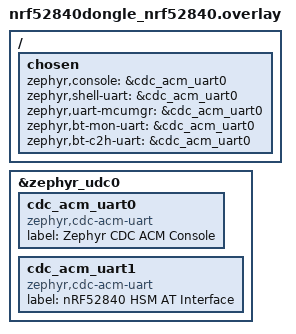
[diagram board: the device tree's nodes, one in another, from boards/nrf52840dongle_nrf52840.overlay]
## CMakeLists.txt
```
cmake_minimum_required(VERSION 3.20.0)

find_package(Zephyr REQUIRED HINTS $ENV{ZEPHYR_BASE})
project(hsm_app)

# Add pure HSM logic library
add_subdirectory(${CMAKE_CURRENT_SOURCE_DIR}/../lib ${CMAKE_CURRENT_BINARY_DIR}/lib)

target_sources(app PRIVATE
    src/main.c
    src/led_status.c
    src/usb_serial.c
    src/dfu_service.c
)

target_link_libraries(app PRIVATE hsm_core)
```

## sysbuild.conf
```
# Dual-Stage Secure Boot Configuration (B0 Immutable -> MCUboot -> Signed App)
SB_CONFIG_BOOTLOADER_MCUBOOT=y
SB_CONFIG_SECURE_BOOT_APPCORE=y
SB_CONFIG_PARTITION_MANAGER=y

# Signature verification using root-level ECDSA P-256 key
SB_CONFIG_BOOT_SIGNATURE_KEY_FILE="../keys/root-ec-p256.pem"
```

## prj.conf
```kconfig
# General Kernel & C library
CONFIG_MAIN_STACK_SIZE=8192
CONFIG_SYSTEM_WORKQUEUE_STACK_SIZE=2048
CONFIG_HEAP_MEM_POOL_SIZE=8192
CONFIG_NEWLIB_LIBC=y
CONFIG_REBOOT=y

# Logging
CONFIG_LOG=y
CONFIG_LOG_MODE_IMMEDIATE=y
CONFIG_LOG_DEFAULT_LEVEL=3
CONFIG_USE_SEGGER_RTT=y
CONFIG_SEGGER_RTT_BUFFER_SIZE_UP=4096
CONFIG_LOG_BACKEND_RTT=y
CONFIG_LOG_BACKEND_UART=y

# Hardware Drivers
CONFIG_GPIO=y
CONFIG_PWM=y
CONFIG_LED=y
CONFIG_LED_PWM=y
CONFIG_HWINFO=y

# Flash & Storage
CONFIG_FLASH=y
CONFIG_FLASH_PAGE_LAYOUT=y
CONFIG_FLASH_MAP=y
CONFIG_STREAM_FLASH=y
CONFIG_NVS=y
CONFIG_SETTINGS=y

# PSA Crypto & CC310 Hardware Acceleration
CONFIG_PSA_CRYPTO=y
CONFIG_PSA_CRYPTO_DRIVER_OBERON=n
CONFIG_PSA_CRYPTO_DRIVER_CC3XX=y
CONFIG_PSA_WANT_ALG_ECDSA=y
CONFIG_PSA_WANT_ALG_ECDH=y
CONFIG_PSA_WANT_ALG_GCM=y
CONFIG_PSA_WANT_KEY_TYPE_AES=y
CONFIG_PSA_WANT_KEY_TYPE_ECC_KEY_PAIR_GENERATE=y
CONFIG_PSA_WANT_KEY_TYPE_ECC_KEY_PAIR_IMPORT=y
CONFIG_PSA_WANT_KEY_TYPE_ECC_KEY_PAIR_EXPORT=y
CONFIG_PSA_WANT_ECC_SECP_R1_256=y
CONFIG_PSA_WANT_ALG_SHA_256=y
CONFIG_PSA_WANT_GENERATE_RANDOM=y
CONFIG_MBEDTLS_PSA_CRYPTO_STORAGE_C=y
CONFIG_SECURE_STORAGE=y
CONFIG_SECURE_STORAGE_ITS_TRANSFORM_AEAD_SCHEME_CHACHA20_POLY1305=y
CONFIG_MBEDTLS_ENABLE_HEAP=y
CONFIG_MBEDTLS_HEAP_SIZE=8192

# USB Device Stack
CONFIG_USB_DEVICE_STACK=y
CONFIG_USB_DEVICE_PRODUCT="nRF52840 HSM Dongle"
CONFIG_USB_DEVICE_MANUFACTURER="pid.codes"
CONFIG_USB_DEVICE_SN="000000000000"
CONFIG_USB_DEVICE_VID=0x1209
CONFIG_USB_DEVICE_PID=0x0001
CONFIG_USB_CDC_ACM=y
CONFIG_USB_COMPOSITE_DEVICE=y
CONFIG_USB_MAX_NUM_TRANSFERS=16
CONFIG_USB_DEVICE_STACK_NEXT=n
CONFIG_UDC_NRF=n
CONFIG_UDC_DRIVER=n
CONFIG_USBD_CDC_ACM_CLASS=n

# Serial & Console over CDC ACM
CONFIG_SERIAL=y
CONFIG_CONSOLE=y
CONFIG_UART_CONSOLE=y
CONFIG_UART_LINE_CTRL=y
CONFIG_RING_BUFFER=y

# Bootloader / DFU MCUboot support
CONFIG_BOOTLOADER_MCUBOOT=y
CONFIG_IMG_MANAGER=y
CONFIG_MCUBOOT_IMG_MANAGER=y
```

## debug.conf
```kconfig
# Debug configuration overlay
CONFIG_LOG_DEFAULT_LEVEL=4
CONFIG_ASSERT=y
CONFIG_ASSERT_LEVEL=2
CONFIG_DEBUG_OPTIMIZATIONS=y
```

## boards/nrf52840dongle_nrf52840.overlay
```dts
/*
 * Devicetree overlay for nRF52840 Dongle (PCA10059)
 * Exposes two CDC ACM Virtual COM Ports:
 *  - cdc_acm_uart0: Zephyr Console & Logging
 *  - cdc_acm_uart1: Dedicated HSM AT Command / Response Channel
 */

/ {
	chosen {
		zephyr,console = &cdc_acm_uart0;
		zephyr,shell-uart = &cdc_acm_uart0;
		zephyr,uart-mcumgr = &cdc_acm_uart0;
		zephyr,bt-mon-uart = &cdc_acm_uart0;
		zephyr,bt-c2h-uart = &cdc_acm_uart0;
	};
};

&zephyr_udc0 {
	/delete-node/ board_cdc_acm_uart;

	cdc_acm_uart0: cdc_acm_uart0 {
		compatible = "zephyr,cdc-acm-uart";
		label = "Zephyr CDC ACM Console";
	};

	cdc_acm_uart1: cdc_acm_uart1 {
		compatible = "zephyr,cdc-acm-uart";
		label = "nRF52840 HSM AT Interface";
	};
};
```

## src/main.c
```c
#include <zephyr/kernel.h>
#include <zephyr/logging/log.h>
#include <hsm/hsm_core.h>
#include <hsm/crypto_cc310.h>
#include <hsm/keystore.h>
#include <hsm/at_commands.h>
#include "led_status.h"
#include "usb_serial.h"
#include "dfu_service.h"

LOG_MODULE_REGISTER(main, CONFIG_LOG_DEFAULT_LEVEL);

static void on_keystore_state_changed(bool authenticated, uint8_t retries, uint8_t key_count) {
    LOG_INF("Keystore state changed: auth=%d, retries=%u, keys=%u",
            authenticated ? 1 : 0, retries, key_count);

    if (retries == 0) {
        /* Blocked / Lockout -> Solid RED */
        led_status_set_state(HSM_STATE_LOCKED);
    } else if (authenticated) {
        /* Authenticated / Unlocked -> Solid GREEN */
        led_status_set_state(HSM_STATE_UNLOCKED);
    } else if (!keystore_is_configured()) {
        /* Unconfigured / Empty -> Breathing WHITE */
        led_status_set_state(HSM_STATE_UNCONFIGURED);
    } else {
        /* Configured but locked -> Solid RED */
        led_status_set_state(HSM_STATE_LOCKED);
    }
}

int main(void) {
    LOG_INF("==================================================");
    LOG_INF(" nRF52840 HSM Dongle Firmware (PCA10059)");
    LOG_INF(" AT Protocol Engine | Dual-Stage Secure Boot");
    LOG_INF(" Arm CryptoCell CC310 Hardware Acceleration");
    LOG_INF("==================================================");

    /* 1. Initialize Visual LED Indicator */
    led_status_init();

    /* 2. Initialize CryptoCell CC310 / PSA Crypto */
    crypto_cc310_init();

    /* 3. Initialize Persistent Keystore & Auth Supervisor */
    keystore_init(on_keystore_state_changed);

    /* 4. Initialize AT Command Processor */
    at_commands_init();

    /* 5. Initialize DFU Flash Service & Register AT Callbacks */
    dfu_service_init();
    static const at_dfu_callbacks_t dfu_cbs = {
        .write_chunk = dfu_service_write_chunk,
        .apply = dfu_service_apply,
        .get_info = dfu_service_get_info,
    };
    at_commands_register_dfu_callbacks(&dfu_cbs);

    /* 6. Initialize Dual USB CDC ACM (Console + AT Protocol) */
    usb_serial_init();
    LOG_INF("Dongle USB Serial (BLE Address): %s", usb_serial_get_ble_address());

    LOG_INF("HSM AT Protocol Engine ready. Entering polling loop...");

    /* Main polling loop */
    while (1) {
        usb_serial_poll();
        k_msleep(2);
    }

    return 0;
}
```

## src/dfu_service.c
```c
#include <zephyr/kernel.h>
#include <zephyr/storage/flash_map.h>
#include <zephyr/dfu/mcuboot.h>
#include <zephyr/sys/reboot.h>
#include <zephyr/logging/log.h>
#include <psa/crypto.h>
#include <string.h>
#include "dfu_service.h"

LOG_MODULE_REGISTER(dfu_service, CONFIG_LOG_DEFAULT_LEVEL);

static struct k_work_delayable s_reboot_work;

static void reboot_work_handler(struct k_work *work) {
    ARG_UNUSED(work);
    LOG_INF("Executing deferred cold reboot into MCUboot...");
    sys_reboot(SYS_REBOOT_COLD);
}

int dfu_service_init(void) {
    k_work_init_delayable(&s_reboot_work, reboot_work_handler);

    if (!boot_is_img_confirmed()) {
        int rc = boot_write_img_confirmed();
        if (rc != 0) {
            LOG_ERR("Failed to confirm running MCUboot image: %d", rc);
        } else {
            LOG_INF("Running MCUboot image confirmed as permanent.");
        }
    }

    LOG_INF("DFU Service initialized for MCUboot secondary slot.");
    return 0;
}

int dfu_service_get_info(uint8_t *major, uint8_t *minor, uint8_t *patch,
                         uint32_t *active_slot, uint32_t *image_size, uint8_t sha256[32]) {
    if (!major || !minor || !patch || !active_slot || !image_size || !sha256) {
        return -1;
    }

    *major = 1;
    *minor = 0;
    *patch = 0;
    *active_slot = 0;
    *image_size = 0;
    memset(sha256, 0, 32);

    const struct flash_area *fa = NULL;
    int rc = flash_area_open(FLASH_AREA_ID(image_0), &fa);
    if (rc != 0 || !fa) {
        LOG_ERR("Failed to open flash area image_0: %d", rc);
        return rc != 0 ? rc : -1;
    }

    uint32_t size_to_hash = (uint32_t)fa->fa_size;
    struct mcuboot_img_header hdr = {0};
    if (boot_read_bank_header(FLASH_AREA_ID(image_0), &hdr, sizeof(hdr)) == 0 &&
        hdr.mcuboot_version == 1 &&
        hdr.h.v1.image_size > 0 &&
        hdr.h.v1.image_size <= fa->fa_size) {
        size_to_hash = hdr.h.v1.image_size;
    }
    *image_size = size_to_hash;

    psa_hash_operation_t op = PSA_HASH_OPERATION_INIT;
    psa_status_t status = psa_hash_setup(&op, PSA_ALG_SHA_256);
    if (status == PSA_SUCCESS) {
        uint8_t buf[256];
        uint32_t offset = 0;
        while (offset < size_to_hash) {
            uint32_t chunk = size_to_hash - offset;
            if (chunk > sizeof(buf)) {
                chunk = sizeof(buf);
            }
            if (flash_area_read(fa, offset, buf, chunk) != 0) {
                psa_hash_abort(&op);
                break;
            }
            if (psa_hash_update(&op, buf, chunk) != PSA_SUCCESS) {
                psa_hash_abort(&op);
                break;
            }
            offset += chunk;
        }
        if (offset == size_to_hash) {
            size_t hash_len = 0;
            (void)psa_hash_finish(&op, sha256, 32, &hash_len);
        }
    }

    flash_area_close(fa);
    return 0;
}

int dfu_service_write_chunk(uint32_t offset, const uint8_t *data, size_t len) {
    const struct flash_area *fa = NULL;
    int rc = flash_area_open(FLASH_AREA_ID(image_1), &fa);
    if (rc != 0) {
        LOG_ERR("Failed to open flash area image_1: %d", rc);
        return rc;
    }

    if (offset == 0) {
        LOG_INF("Erasing secondary slot before write...");
        rc = flash_area_erase(fa, 0, fa->fa_size);
        if (rc != 0) {
            LOG_ERR("Failed to erase slot 1: %d", rc);
            flash_area_close(fa);
            return rc;
        }
    }

    /* Align write length to 4-byte flash write word boundary (padding with 0xFF) */
    const uint8_t *write_buf = data;
    uint8_t padded_buf[256 + 4];
    size_t write_len = len;

    size_t rem = len % 4;
    if (rem != 0) {
        size_t pad = 4 - rem;
        write_len = len + pad;
        if (write_len <= sizeof(padded_buf)) {
            memcpy(padded_buf, data, len);
            memset(padded_buf + len, 0xff, pad);
            write_buf = padded_buf;
        }
    }

    rc = flash_area_write(fa, offset, write_buf, write_len);
    flash_area_close(fa);

    if (rc != 0) {
        LOG_ERR("Failed to write chunk at offset 0x%x (len %zu): %d", offset, len, rc);
        return rc;
    }

    return 0;
}

int dfu_service_apply(void) {
    LOG_INF("Marking MCUboot upgrade image for test...");
    int rc = boot_request_upgrade(BOOT_UPGRADE_TEST);
    if (rc != 0) {
        LOG_ERR("boot_request_upgrade failed: %d", rc);
        return rc;
    }

    LOG_INF("Scheduling cold reboot into MCUboot in 200 ms...");
    k_work_schedule(&s_reboot_work, K_MSEC(200));
    return 0;
}
```

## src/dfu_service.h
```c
#ifndef DFU_SERVICE_H_
#define DFU_SERVICE_H_

#include <stdint.h>
#include <stddef.h>

#ifdef __cplusplus
extern "C" {
#endif

int dfu_service_init(void);
int dfu_service_write_chunk(uint32_t offset, const uint8_t *data, size_t len);
int dfu_service_apply(void);
int dfu_service_get_info(uint8_t *major, uint8_t *minor, uint8_t *patch,
                         uint32_t *active_slot, uint32_t *image_size, uint8_t sha256[32]);

#ifdef __cplusplus
}
#endif

#endif /* DFU_SERVICE_H_ */
```

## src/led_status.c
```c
#include <zephyr/kernel.h>
#include <zephyr/drivers/gpio.h>
#include <zephyr/drivers/pwm.h>
#include <zephyr/logging/log.h>
#include "led_status.h"

LOG_MODULE_REGISTER(led_status, CONFIG_LOG_DEFAULT_LEVEL);

/* RGB LED GPIO nodes on PCA10059 */
static const struct gpio_dt_spec s_led_red   = GPIO_DT_SPEC_GET(DT_NODELABEL(led1_red), gpios);
static const struct gpio_dt_spec s_led_green = GPIO_DT_SPEC_GET(DT_NODELABEL(led1_green), gpios);
static const struct gpio_dt_spec s_led_blue  = GPIO_DT_SPEC_GET(DT_NODELABEL(led1_blue), gpios);

/* RGB LED PWM nodes on PCA10059 */
#if DT_NODE_EXISTS(DT_NODELABEL(red_pwm_led))
static const struct pwm_dt_spec s_pwm_red = PWM_DT_SPEC_GET(DT_NODELABEL(red_pwm_led));
#endif

#if DT_NODE_EXISTS(DT_NODELABEL(green_pwm_led))
static const struct pwm_dt_spec s_pwm_green = PWM_DT_SPEC_GET(DT_NODELABEL(green_pwm_led));
#endif

#if DT_NODE_EXISTS(DT_NODELABEL(blue_pwm_led))
static const struct pwm_dt_spec s_pwm_blue = PWM_DT_SPEC_GET(DT_NODELABEL(blue_pwm_led));
#endif

static volatile hsm_state_t s_current_state = HSM_STATE_UNCONFIGURED;
static struct k_thread s_led_thread;
static K_THREAD_STACK_DEFINE(s_led_stack, 1024);
static struct k_sem s_state_sem;

static void led_thread_fn(void *arg1, void *arg2, void *arg3) {
    ARG_UNUSED(arg1);
    ARG_UNUSED(arg2);
    ARG_UNUSED(arg3);

    bool pwm_red_ready = false;
    bool pwm_green_ready = false;
    bool pwm_blue_ready = false;

#if DT_NODE_EXISTS(DT_NODELABEL(red_pwm_led))
    pwm_red_ready = device_is_ready(s_pwm_red.dev);
#endif
#if DT_NODE_EXISTS(DT_NODELABEL(green_pwm_led))
    pwm_green_ready = device_is_ready(s_pwm_green.dev);
#endif
#if DT_NODE_EXISTS(DT_NODELABEL(blue_pwm_led))
    pwm_blue_ready = device_is_ready(s_pwm_blue.dev);
#endif

    int breath_counter = 0;
    int breath_dir = 1;

    while (1) {
        hsm_state_t st = s_current_state;

        switch (st) {
        case HSM_STATE_UNCONFIGURED: {
            /*
             * Synchronous white breathing glow across Red, Green, and Blue channels.
             * 3.0s total period: 50 steps up + 50 steps down at 30ms/step = 3000ms.
             */
            uint32_t duty = (uint32_t)(breath_counter * 2); /* 0% to 100% */

            if (pwm_red_ready) {
                uint32_t pulse_r = (uint32_t)((uint64_t)s_pwm_red.period * duty / 100);
                pwm_set_pulse_dt(&s_pwm_red, pulse_r);
            }
            if (pwm_green_ready) {
                uint32_t pulse_g = (uint32_t)((uint64_t)s_pwm_green.period * duty / 100);
                pwm_set_pulse_dt(&s_pwm_green, pulse_g);
            }
            if (pwm_blue_ready) {
                uint32_t pulse_b = (uint32_t)((uint64_t)s_pwm_blue.period * duty / 100);
                pwm_set_pulse_dt(&s_pwm_blue, pulse_b);
            }

            if (!pwm_red_ready || !pwm_green_ready || !pwm_blue_ready) {
                int on = (duty > 50) ? 1 : 0;
                gpio_pin_set_dt(&s_led_red, on);
                gpio_pin_set_dt(&s_led_green, on);
                gpio_pin_set_dt(&s_led_blue, on);
            }

            breath_counter += breath_dir;
            if (breath_counter >= 50) {
                breath_counter = 50;
                breath_dir = -1;
            } else if (breath_counter <= 0) {
                breath_counter = 0;
                breath_dir = 1;
            }

            /* Wait 30ms or wake immediately upon state transition */
            (void)k_sem_take(&s_state_sem, K_MSEC(30));
            break;
        }

        case HSM_STATE_LOCKED: {
            /*
             * Configured & Locked State:
             * Blue and Green strictly 0% (OFF), Red 100% solid ON.
             */
            if (pwm_blue_ready) {
                pwm_set_pulse_dt(&s_pwm_blue, 0);
            }
            if (pwm_green_ready) {
                pwm_set_pulse_dt(&s_pwm_green, 0);
            }
            if (pwm_red_ready) {
                pwm_set_pulse_dt(&s_pwm_red, s_pwm_red.period);
            }

            gpio_pin_set_dt(&s_led_blue, 0);
            gpio_pin_set_dt(&s_led_green, 0);
            gpio_pin_set_dt(&s_led_red, 1);

            /* Sleep until next state transition signal */
            (void)k_sem_take(&s_state_sem, K_FOREVER);
            break;
        }

        case HSM_STATE_UNLOCKED: {
            /*
             * Authenticated State:
             * Red and Blue strictly OFF (0%), Green 100% solid ON.
             */
            if (pwm_red_ready) {
                pwm_set_pulse_dt(&s_pwm_red, 0);
            }
            if (pwm_blue_ready) {
                pwm_set_pulse_dt(&s_pwm_blue, 0);
            }
            if (pwm_green_ready) {
                pwm_set_pulse_dt(&s_pwm_green, s_pwm_green.period);
            }

            gpio_pin_set_dt(&s_led_red, 0);
            gpio_pin_set_dt(&s_led_blue, 0);
            gpio_pin_set_dt(&s_led_green, 1);

            /* Sleep until next state transition signal */
            (void)k_sem_take(&s_state_sem, K_FOREVER);
            break;
        }
        }
    }
}

int led_status_init(void) {
    k_sem_init(&s_state_sem, 0, 1);

    if (!gpio_is_ready_dt(&s_led_red) || !gpio_is_ready_dt(&s_led_green) || !gpio_is_ready_dt(&s_led_blue)) {
        LOG_WRN("GPIO LED devices not all ready");
    }

    gpio_pin_configure_dt(&s_led_red, GPIO_OUTPUT_INACTIVE);
    gpio_pin_configure_dt(&s_led_green, GPIO_OUTPUT_INACTIVE);
    gpio_pin_configure_dt(&s_led_blue, GPIO_OUTPUT_INACTIVE);

    k_thread_create(&s_led_thread, s_led_stack,
                    K_THREAD_STACK_SIZEOF(s_led_stack),
                    led_thread_fn,
                    NULL, NULL, NULL,
                    K_PRIO_COOP(7), 0, K_NO_WAIT);
    k_thread_name_set(&s_led_thread, "led_status");

    return 0;
}

void led_status_set_state(hsm_state_t state) {
    s_current_state = state;
    /* Wake thread immediately (< 50ms) */
    k_sem_give(&s_state_sem);
}
```

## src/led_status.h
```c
#ifndef LED_STATUS_H_
#define LED_STATUS_H_

#include <hsm/hsm_core.h>

#ifdef __cplusplus
extern "C" {
#endif

int led_status_init(void);
void led_status_set_state(hsm_state_t state);

#ifdef __cplusplus
}
#endif

#endif /* LED_STATUS_H_ */
```

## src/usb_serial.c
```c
#include <zephyr/kernel.h>
#include <zephyr/device.h>
#include <zephyr/drivers/uart.h>
#include <zephyr/drivers/hwinfo.h>
#include <zephyr/usb/usb_device.h>
#include <zephyr/usb/usb_ch9.h>
#include <zephyr/logging/log.h>
#include <hal/nrf_ficr.h>
#include <stdio.h>
#include <string.h>
#include <hsm/at_parser.h>
#include <hsm/at_commands.h>
#include "usb_serial.h"

LOG_MODULE_REGISTER(usb_serial, CONFIG_LOG_DEFAULT_LEVEL);

#ifndef USB_BSTRING_LENGTH
#define USB_BSTRING_LENGTH(s) (sizeof(s) * 2 - 2)
#endif
#ifndef USB_STRING_DESCRIPTOR_LENGTH
#define USB_STRING_DESCRIPTOR_LENGTH(s) (sizeof(s) * 2)
#endif

#define CONSOLE_IF_STR "Zephyr CDC ACM Console"
#define HSM_IF_STR     "nRF52840 HSM AT Interface"

struct usb_console_if_string_desc {
	uint8_t bLength;
	uint8_t bDescriptorType;
	uint8_t bString[USB_BSTRING_LENGTH(CONSOLE_IF_STR)];
} __packed;

struct usb_hsm_if_string_desc {
	uint8_t bLength;
	uint8_t bDescriptorType;
	uint8_t bString[USB_BSTRING_LENGTH(HSM_IF_STR)];
} __packed;

USBD_STRING_DESCR_USER_DEFINE(primary) struct usb_console_if_string_desc s_console_str_desc = {
	.bLength = USB_STRING_DESCRIPTOR_LENGTH(CONSOLE_IF_STR),
	.bDescriptorType = USB_DESC_STRING,
	.bString = CONSOLE_IF_STR,
};

USBD_STRING_DESCR_USER_DEFINE(primary) struct usb_hsm_if_string_desc s_hsm_str_desc = {
	.bLength = USB_STRING_DESCRIPTOR_LENGTH(HSM_IF_STR),
	.bDescriptorType = USB_DESC_STRING,
	.bString = HSM_IF_STR,
};

static const struct device *s_uart_hsm = DEVICE_DT_GET(DT_NODELABEL(cdc_acm_uart1));

static at_parser_t s_parser;
static char s_line_buf[AT_PARSER_MAX_LINE_LEN];
static char s_resp_buf[1024];

static char s_ble_sn[13];
static bool s_ble_sn_ready;

static void compute_ble_sn(void)
{
	if (s_ble_sn_ready) {
		return;
	}

	uint32_t addr1 = 0;
	uint32_t addr0 = 0;

#if defined(NRF_FICR)
	addr1 = NRF_FICR->DEVICEADDR[1] & 0x0000FFFFUL;
	addr0 = NRF_FICR->DEVICEADDR[0];

	/* If Random Static Address type per BLE spec, set upper two bits */
	if ((NRF_FICR->DEVICEADDRTYPE & 0x01UL) != 0) {
		addr1 |= 0x0000C000UL;
	}

	/* Fallback to DEVICEID if DEVICEADDR is blank/unprogrammed */
	if ((addr0 == 0xFFFFFFFFUL && (addr1 & 0xFFFFUL) == 0xFFFFUL) ||
	    (addr0 == 0 && (addr1 & 0xFFFFUL) == 0)) {
		addr0 = NRF_FICR->DEVICEID[0];
		addr1 = NRF_FICR->DEVICEID[1] & 0x0000FFFFUL;
	}
#endif

	/* Fallback to hwinfo driver if FICR still blank */
	if ((addr0 == 0xFFFFFFFFUL && (addr1 & 0xFFFFUL) == 0xFFFFUL) ||
	    (addr0 == 0 && (addr1 & 0xFFFFUL) == 0)) {
		uint8_t hwid[6] = {0};
		ssize_t hwlen = hwinfo_get_device_id(hwid, sizeof(hwid));
		if (hwlen > 0) {
			addr1 = ((uint32_t)hwid[0] << 8) | hwid[1];
			addr0 = ((uint32_t)hwid[2] << 24) | ((uint32_t)hwid[3] << 16) |
				((uint32_t)hwid[4] << 8) | hwid[5];
		} else {
			addr1 = 0x0000C0DEUL;
			addr0 = 0xCAFE0001UL;
		}
	}

	/* Format into a 12-character uppercase hex string (MSB-to-LSB) */
	snprintf(s_ble_sn, sizeof(s_ble_sn), "%04X%08X",
		 (unsigned int)(addr1 & 0xFFFFUL), (unsigned int)addr0);
	s_ble_sn_ready = true;
}

/* Override Zephyr's weak hook to return the dynamic 12-char BLE serial number */
uint8_t *usb_update_sn_string_descriptor(void)
{
	compute_ble_sn();
	return (uint8_t *)s_ble_sn;
}

const char *usb_serial_get_ble_address(void)
{
	compute_ble_sn();
	return s_ble_sn;
}

extern uint8_t *usb_get_device_descriptor(void);
extern int usb_get_str_descriptor_idx(void *ptr);
extern struct usb_desc_header __usb_descriptor_start[];

static int usb_serial_patch_descriptors(void)
{
	/* Force descriptor table generation & fixup first */
	uint8_t *dev_desc = usb_get_device_descriptor();
	if (!dev_desc) {
		LOG_ERR("Failed to get device descriptor");
		return -EINVAL;
	}

	int console_idx = usb_get_str_descriptor_idx(&s_console_str_desc);
	int hsm_idx = usb_get_str_descriptor_idx(&s_hsm_str_desc);

	LOG_DBG("String descriptor indices: console=%d, hsm=%d", console_idx, hsm_idx);

	struct usb_desc_header *head = __usb_descriptor_start;
	while (head->bLength != 0U) {
		if (head->bDescriptorType == USB_DESC_INTERFACE) {
			struct usb_if_descriptor *if_desc = (struct usb_if_descriptor *)head;
			if (if_desc->bInterfaceNumber == 0) {
				if_desc->bInterfaceProtocol = 0x01;
				if (console_idx > 0) {
					if_desc->iInterface = (uint8_t)console_idx;
				}
				LOG_INF("Patched Interface 0 (Console): proto=0x0001, iInterface=%u",
					if_desc->iInterface);
			} else if (if_desc->bInterfaceNumber == 2) {
				if_desc->bInterfaceProtocol = 0x01;
				if (hsm_idx > 0) {
					if_desc->iInterface = (uint8_t)hsm_idx;
				}
				LOG_INF("Patched Interface 2 (HSM AT): proto=0x%02x, iInterface=%u",
					if_desc->bInterfaceProtocol, if_desc->iInterface);
			}
		} else if (head->bDescriptorType == USB_DESC_INTERFACE_ASSOC) {
			struct usb_association_descriptor *iad = (struct usb_association_descriptor *)head;
			if (iad->bFirstInterface == 0) {
				iad->bFunctionProtocol = 0x01;
				if (console_idx > 0) {
					iad->iFunction = (uint8_t)console_idx;
				}
			} else if (iad->bFirstInterface == 2) {
				iad->bFunctionProtocol = 0x01;
				if (hsm_idx > 0) {
					iad->iFunction = (uint8_t)hsm_idx;
				}
			}
		}

		head = (struct usb_desc_header *)((uint8_t *)head + head->bLength);
	}

	return 0;
}

void usb_serial_write_at_response(const char *resp) {
	if (!s_uart_hsm || !device_is_ready(s_uart_hsm) || !resp) {
		return;
	}
	size_t len = strlen(resp);
	for (size_t i = 0; i < len; i++) {
		uart_poll_out(s_uart_hsm, (unsigned char)resp[i]);
	}
}

void usb_serial_poll(void) {
	if (!s_uart_hsm || !device_is_ready(s_uart_hsm)) {
		return;
	}

	uint8_t c;
	while (uart_poll_in(s_uart_hsm, &c) == 0) {
		bool line_ready = false;
		int rc = at_parser_feed(&s_parser, c, s_line_buf, sizeof(s_line_buf), &line_ready);

		if (rc < 0) {
			/* Overflow detected */
			at_commands_format_error(s_resp_buf, sizeof(s_resp_buf), CME_ERR_BUFFER_OVERFLOW);
			usb_serial_write_at_response(s_resp_buf);
			continue;
		}

		if (line_ready) {
			LOG_DBG("AT CMD RX: %s", s_line_buf);
			s_resp_buf[0] = '\0';
			int exec_rc = at_commands_execute(s_line_buf, s_resp_buf, sizeof(s_resp_buf));
			if (exec_rc == 0 && s_resp_buf[0] != '\0') {
				LOG_DBG("AT RESP TX: %s", s_resp_buf);
				usb_serial_write_at_response(s_resp_buf);
			}
		}
	}
}

int usb_serial_init(void) {
	at_parser_init(&s_parser);

	/* Pre-compute dynamic serial number */
	compute_ble_sn();
	LOG_INF("USB Serial Number (BLE Address): %s", s_ble_sn);

	/* Patch descriptors before enabling USB stack */
	int ret = usb_serial_patch_descriptors();
	if (ret != 0) {
		LOG_WRN("Descriptor patching returned %d", ret);
	}

	ret = usb_enable(NULL);
	if (ret != 0) {
		LOG_ERR("Failed to enable USB: %d", ret);
		return ret;
	}

	LOG_INF("Dual USB CDC ACM stack initialized successfully.");
	return 0;
}
```

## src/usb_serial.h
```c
#ifndef USB_SERIAL_H_
#define USB_SERIAL_H_

#include <stddef.h>

#ifdef __cplusplus
extern "C" {
#endif

int usb_serial_init(void);
void usb_serial_poll(void);
void usb_serial_write_at_response(const char *resp);
const char *usb_serial_get_ble_address(void);

#ifdef __cplusplus
}
#endif

#endif /* USB_SERIAL_H_ */
```
